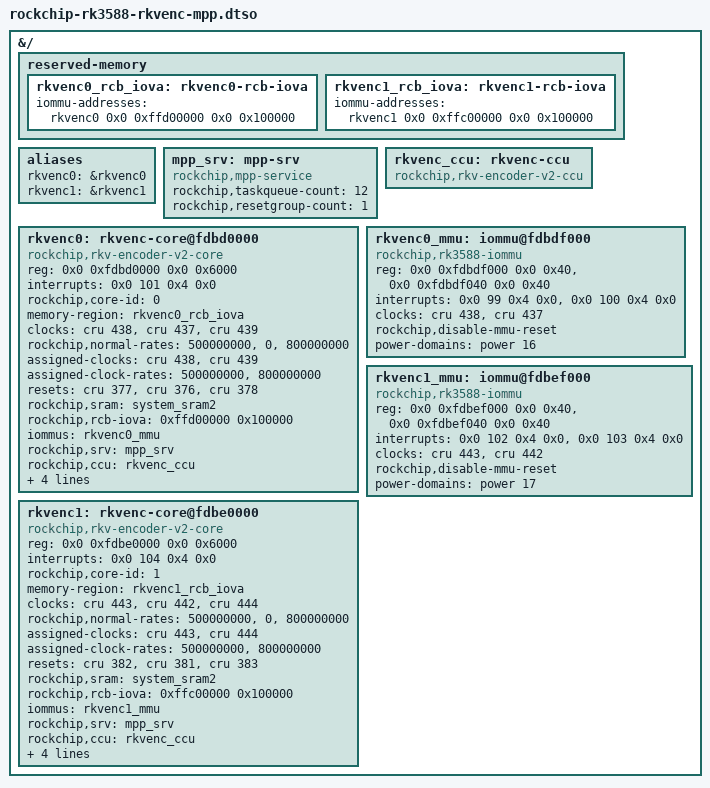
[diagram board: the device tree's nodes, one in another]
// SPDX-License-Identifier: (GPL-2.0+ OR MIT)
/*
 * DTS overlay for Rockchip RK3588 VEPU580 H.265/H.264 encoder
 * (rkvenc driver via MPP framework)
 *
 * Enables: mpp-srv, rkvenc-ccu, rkvenc0/1 encoder cores, rkvenc0/1 IOMMUs
 * Clock rates follow Rockchip BSP: 500 MHz aclk, 800 MHz core
 *
 * Usage:
 *   armbian-add-overlay rockchip-rk3588-rkvenc-mpp.dts
 *   reboot
 *
 * Copyright (C) 2026 Ross Cawston
 */

/dts-v1/;
/plugin/;

/*
 * Raw numeric values (no C preprocessor needed):
 *   Clock IDs:  ACLK_RKVENC0=438  HCLK_RKVENC0=437  CLK_RKVENC0_CORE=439
 *               ACLK_RKVENC1=443  HCLK_RKVENC1=442  CLK_RKVENC1_CORE=444
 *   Reset IDs:  SRST_A_RKVENC0=377  SRST_H_RKVENC0=376  SRST_RKVENC0_CORE=378
 *               SRST_A_RKVENC1=382  SRST_H_RKVENC1=381  SRST_RKVENC1_CORE=383
 *   Power:      RK3588_PD_VENC0=16  RK3588_PD_VENC1=17
 *   GIC_SPI=0   IRQ_TYPE_LEVEL_HIGH=4
 */

/*
 * Single root fragment — must declare #address-cells/#size-cells so
 * U-Boot's fdt_overlay_apply() can parse reg properties correctly.
 */
&{/} {
	#address-cells = <2>;
	#size-cells = <2>;

	reserved-memory {
		#address-cells = <2>;
		#size-cells = <2>;
		ranges;

		rkvenc0_rcb_iova: rkvenc0-rcb-iova {
			iommu-addresses = <&rkvenc0 0x0 0xffd00000 0x0 0x100000>;
		};

		rkvenc1_rcb_iova: rkvenc1-rcb-iova {
			iommu-addresses = <&rkvenc1 0x0 0xffc00000 0x0 0x100000>;
		};
	};

	/* Aliases for core ID assignment (of_alias_get_id) */
	aliases {
		rkvenc0 = &rkvenc0;
		rkvenc1 = &rkvenc1;
	};

	/* MPP service */
	mpp_srv: mpp-srv {
		compatible = "rockchip,mpp-service";
		rockchip,taskqueue-count = <12>;
		rockchip,resetgroup-count = <1>;
	};

	/* CCU — dual-core coordination unit */
	rkvenc_ccu: rkvenc-ccu {
		compatible = "rockchip,rkv-encoder-v2-ccu";
	};

	/* Encoder core 0 — VEPU580 @ 0xfdbd0000 */
	rkvenc0: rkvenc-core@fdbd0000 {
		compatible = "rockchip,rkv-encoder-v2-core";
		reg = <0x0 0xfdbd0000 0x0 0x6000>;
		interrupts = <0x0 101 0x4 0x0>;
		interrupt-names = "irq_rkvenc0";
		rockchip,core-id = <0>;
		memory-region = <&rkvenc0_rcb_iova>;
		clocks = <&cru 438>, <&cru 437>, <&cru 439>;
		clock-names = "aclk_vcodec", "hclk_vcodec", "clk_core";
		rockchip,normal-rates = <500000000>, <0>, <800000000>;
		assigned-clocks = <&cru 438>, <&cru 439>;
		assigned-clock-rates = <500000000>, <800000000>;
		resets = <&cru 377>, <&cru 376>, <&cru 378>;
		reset-names = "video_a", "video_h", "video_core";
		rockchip,sram = <&system_sram2>;
		rockchip,rcb-iova = <0xffd00000 0x100000>;
		iommus = <&rkvenc0_mmu>;
		rockchip,srv = <&mpp_srv>;
		rockchip,ccu = <&rkvenc_ccu>;
		rockchip,taskqueue-node = <7>;
		rockchip,resetgroup-node = <0>;
		rockchip,task-capacity = <8>;
		power-domains = <&power 16>;
	};

	/* IOMMU for encoder core 0 */
	rkvenc0_mmu: iommu@fdbdf000 {
		compatible = "rockchip,rk3588-iommu", "rockchip,rk3568-iommu";
		reg = <0x0 0xfdbdf000 0x0 0x40>, <0x0 0xfdbdf040 0x0 0x40>;
		interrupts = <0x0 99 0x4 0x0>, <0x0 100 0x4 0x0>;
		clocks = <&cru 438>, <&cru 437>;
		clock-names = "aclk", "iface";
		rockchip,disable-mmu-reset;
		#iommu-cells = <0>;
		power-domains = <&power 16>;
	};

	/* Encoder core 1 — VEPU580 @ 0xfdbe0000 */
	rkvenc1: rkvenc-core@fdbe0000 {
		compatible = "rockchip,rkv-encoder-v2-core";
		reg = <0x0 0xfdbe0000 0x0 0x6000>;
		interrupts = <0x0 104 0x4 0x0>;
		interrupt-names = "irq_rkvenc1";
		rockchip,core-id = <1>;
		memory-region = <&rkvenc1_rcb_iova>;
		clocks = <&cru 443>, <&cru 442>, <&cru 444>;
		clock-names = "aclk_vcodec", "hclk_vcodec", "clk_core";
		rockchip,normal-rates = <500000000>, <0>, <800000000>;
		assigned-clocks = <&cru 443>, <&cru 444>;
		assigned-clock-rates = <500000000>, <800000000>;
		resets = <&cru 382>, <&cru 381>, <&cru 383>;
		reset-names = "video_a", "video_h", "video_core";
		rockchip,sram = <&system_sram2>;
		rockchip,rcb-iova = <0xffc00000 0x100000>;
		iommus = <&rkvenc1_mmu>;
		rockchip,srv = <&mpp_srv>;
		rockchip,ccu = <&rkvenc_ccu>;
		rockchip,taskqueue-node = <7>;
		rockchip,resetgroup-node = <0>;
		rockchip,task-capacity = <8>;
		power-domains = <&power 17>;
	};

	/* IOMMU for encoder core 1 */
	rkvenc1_mmu: iommu@fdbef000 {
		compatible = "rockchip,rk3588-iommu", "rockchip,rk3568-iommu";
		reg = <0x0 0xfdbef000 0x0 0x40>, <0x0 0xfdbef040 0x0 0x40>;
		interrupts = <0x0 102 0x4 0x0>, <0x0 103 0x4 0x0>;
		clocks = <&cru 443>, <&cru 442>;
		clock-names = "aclk", "iface";
		rockchip,disable-mmu-reset;
		#iommu-cells = <0>;
		power-domains = <&power 17>;
	};
};
